# M3V6 register map
File version: 0.1
Registers are 32-bit, read-write, reset 0x0 unless marked. A register's access mark holds for its fields unless they carry their own. Offsets are from the block's base; [hi:lo] are bit positions; {n}, {i} and the like mark numbered series.

## PM — General Purpose Input_Output Port (PM)
Base 0x40000300
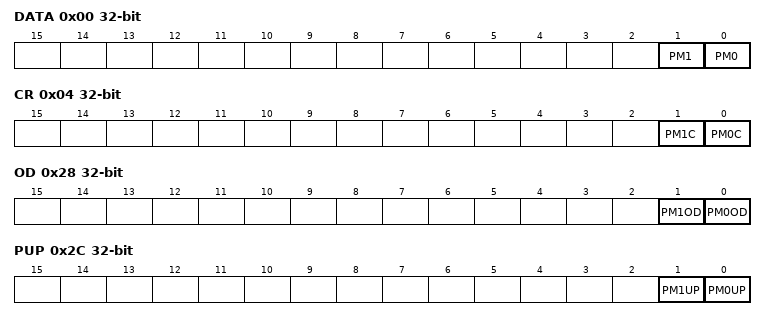
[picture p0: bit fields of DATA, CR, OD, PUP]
0x00 DATA — PM Data Register
  [1] PM1, [0] PM0
0x04 CR — PM Control Register
  [1] PM1C, [0] PM0C
0x28 OD — PM Open Drain Control Register
  [1] PM1OD, [0] PM0OD
0x2C PUP — PM Pull-Up Control Register
  [1] PM1UP, [0] PM0UP
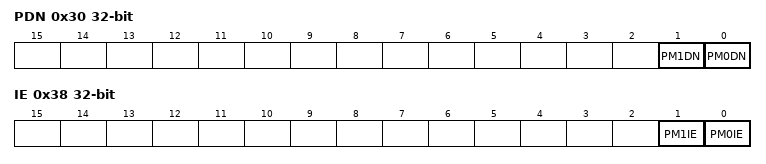
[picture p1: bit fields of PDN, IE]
0x30 PDN — PM Pull-Down Control Register
  [1] PM1DN, [0] PM0DN
0x38 IE — PM Input Enable Control Register
  [1] PM1IE, [0] PM0IE

## PN — General Purpose Input_Output Port (PN)
Base 0x40000340
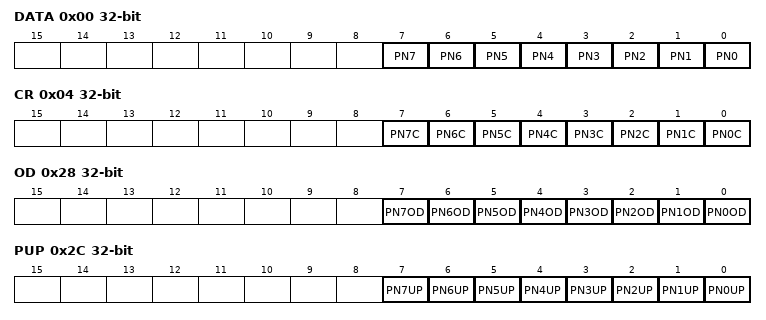
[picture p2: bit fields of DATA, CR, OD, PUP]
0x00 DATA — PN Data Register
  [n] PN{n} (n=0..7)
0x04 CR — PN Control Register
  [n] PN{n}C (n=0..7)
0x0C FR2 — PN Function Register 2
  [7] PN7F2
0x28 OD — PN Open Drain Control Register
  [n] PN{n}OD (n=0..7)
0x2C PUP — PN Pull-Up Control Register
  [n] PN{n}UP (n=0..7)
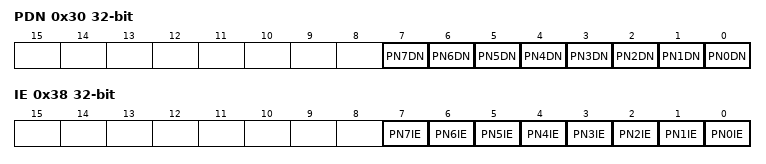
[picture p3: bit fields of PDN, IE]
0x30 PDN — PN Pull-Down Control Register
  [n] PN{n}DN (n=0..7)
0x38 IE — PN Input Enable Control Register
  [n] PN{n}IE (n=0..7)

## PP — General Purpose Input_Output Port (PP)
Base 0x40000380
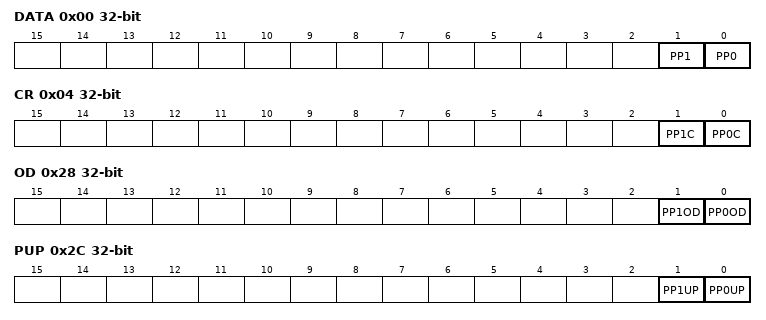
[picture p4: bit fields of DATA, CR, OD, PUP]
0x00 DATA — PP Data Register
  [1] PP1, [0] PP0
0x04 CR — PP Control Register
  [1] PP1C, [0] PP0C
0x28 OD — PP Open Drain Control Register
  [1] PP1OD, [0] PP0OD
0x2C PUP — PP Pull-Up Control Register
  [1] PP1UP, [0] PP0UP
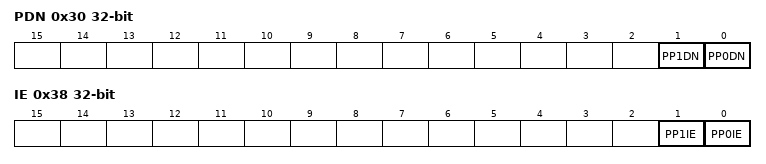
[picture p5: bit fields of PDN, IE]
0x30 PDN — PP Pull-Down Control Register
  [1] PP1DN, [0] PP0DN
0x38 IE — PP Input Enable Control Register
  [1] PP1IE, [0] PP0IE

## TB0 — 16-bit Timer_Event Counter (TB)
Base 0x40010000
Same registers: TB1 0x40010040, TB2 0x40010080, TB3 0x400100C0, TB4 0x40010100, TB5 0x40010140, TB6 0x40010180, TB7 0x400101C0
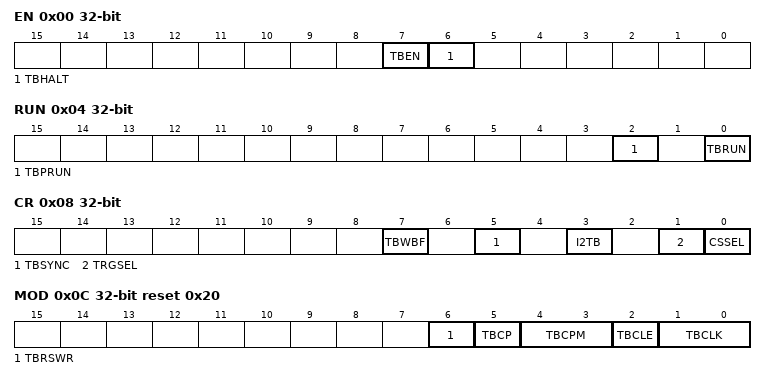
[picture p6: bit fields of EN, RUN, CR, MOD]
0x00 EN — TB Enable Register
  [7] TBEN, [6] TBHALT
0x04 RUN — TB RUN Register
  [2] TBPRUN, [0] TBRUN
0x08 CR — TB Control Register
  [7] TBWBF, [5] TBSYNC, [3] I2TB, [1] TRGSEL, [0] CSSEL
0x0C MOD reset 0x20 — TB Mode Register
  [6] TBRSWR, [5] TBCP wo, [4:3] TBCPM, [2] TBCLE, [1:0] TBCLK
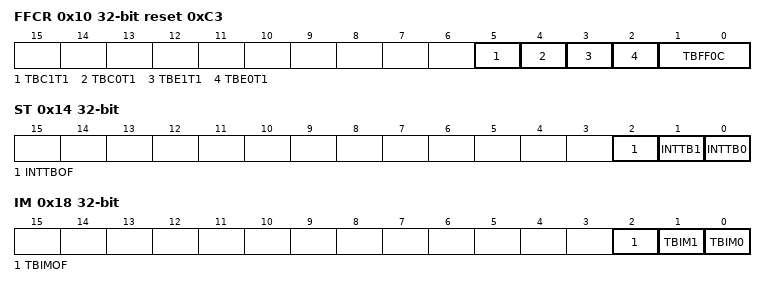
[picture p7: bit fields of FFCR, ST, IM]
0x10 FFCR reset 0xC3 — TB Flip-Flop Control Register
  [5] TBC1T1, [4] TBC0T1, [3] TBE1T1, [2] TBE0T1, [1:0] TBFF0C
0x14 ST ro — TB Status Register
  [2] INTTBOF, [1] INTTB1, [0] INTTB0
0x18 IM — TB Interrupt Mask Register
  [2] TBIMOF, [1] TBIM1, [0] TBIM0
0x1C UC ro — TB Read Capture Register
  [15:0] TBUC
0x20 RG0 — TB RG0 Timer Register
  [15:0] TBRG0
0x24 RG1 — TB RG1 Timer Register
  [15:0] TBRG1
0x28 CP0 ro (reset mask 0xFFFF0000) — TB CP0 Capture Register
  [15:0] TBCP0
0x2C CP1 ro (reset mask 0xFFFF0000) — TB CP1 Capture Register
  [15:0] TBCP1

## SBI — Serial Bus Interface (SBI)
Base 0x40020000
0x00 CR0 — SBI Control Register 0
  [7] SBIEN
0x04 CR1_A reset 0x9 — SBI Control Register 1 (I2C Mode)
  [7:5] BC, [4] ACK, [2:1] SCK12, [0] SWRMON ro, [0] SCK0 wo
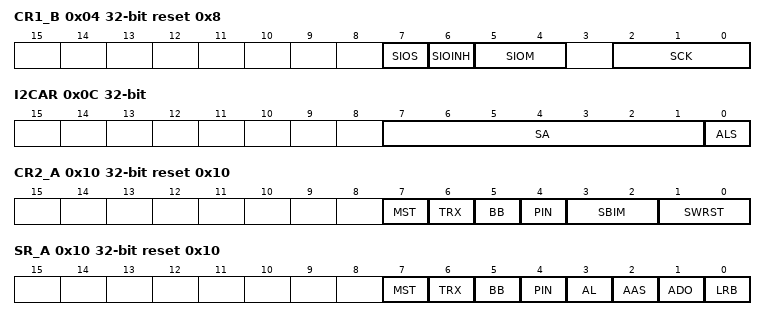
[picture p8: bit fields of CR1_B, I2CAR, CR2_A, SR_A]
0x04 CR1_B reset 0x8 (SBI_CR1 view) — SBI Control Register 1 (SIO Mode)
  [7] SIOS, [6] SIOINH, [5:4] SIOM, [2:0] SCK
0x08 DBR — SBI Data Buffer Register
  [7:0] DB
0x0C I2CAR — SBI I2C Bus Address Register
  [7:1] SA, [0] ALS
0x10 CR2_A wo reset 0x10 — SBI Control Register 2 (I2C Mode)
  [7] MST, [6] TRX, [5] BB, [4] PIN, [3:2] SBIM, [1:0] SWRST
0x10 CR2_B wo reset 0xF3 (SBI_CR2 view) — SBI Control Register 2 (SIO Mode)
  [3:2] SBIM
0x10 SR_A ro reset 0x10 — SBI Status Register (I2C Mode)
  [7] MST, [6] TRX, [5] BB, [4] PIN, [3] AL, [2] AAS, [1] ADO, [0] LRB
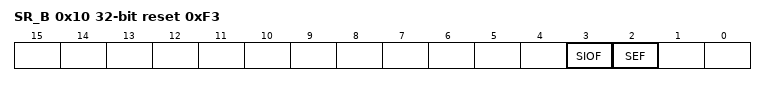
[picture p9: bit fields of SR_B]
0x10 SR_B ro reset 0xF3 (SBI_SR view) — SBI Status Register (SIO Mode)
  [3] SIOF, [2] SEF
0x14 BR0 reset 0xBE — SBI Baud Rate Register 0
  [6] I2SBI

## SC0 — Serial Channel (SC)
Base 0x40020080
Same registers: SC1 0x400200C0, SC2 0x40020100
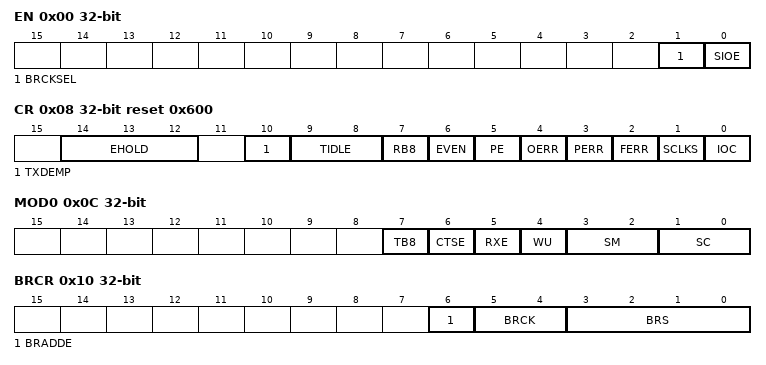
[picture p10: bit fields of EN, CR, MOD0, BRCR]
0x00 EN — SC Enable Register
  [1] BRCKSEL, [0] SIOE
0x04 BUF — SC Buffer Register
  [7:0] TB_RB
0x08 CR reset 0x600 — SC Control Register
  [14:12] EHOLD, [10] TXDEMP, [9:8] TIDLE, [7] RB8 ro, [6] EVEN, [5] PE, [4] OERR ro, [3] PERR ro, [2] FERR ro, [1] SCLKS, [0] IOC
0x0C MOD0 — SC Mode Control Register 0
  [7] TB8, [6] CTSE, [5] RXE, [4] WU, [3:2] SM, [1:0] SC
0x10 BRCR — SC Baud Rate Generator Control Register
  [6] BRADDE, [5:4] BRCK, [3:0] BRS
0x14 BRADD — SC Baud Rate Generator Control Register 2
  [3:0] BRK
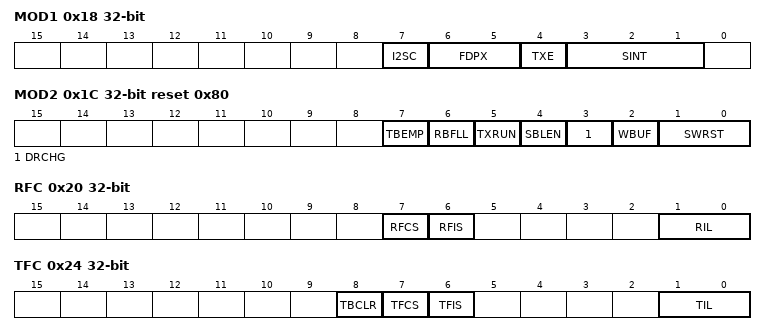
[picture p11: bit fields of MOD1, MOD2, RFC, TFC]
0x18 MOD1 — SC Mode Control Register 1
  [7] I2SC, [6:5] FDPX, [4] TXE, [3:1] SINT
0x1C MOD2 reset 0x80 — SC Mode Control Register 2
  [7] TBEMP ro, [6] RBFLL ro, [5] TXRUN ro, [4] SBLEN, [3] DRCHG, [2] WBUF, [1:0] SWRST
0x20 RFC — SC RX FIFO Configuration Register
  [7] RFCS wo, [6] RFIS, [1:0] RIL
0x24 TFC — SC TX FIFO Configuration Register
  [8] TBCLR wo, [7] TFCS wo, [6] TFIS, [1:0] TIL
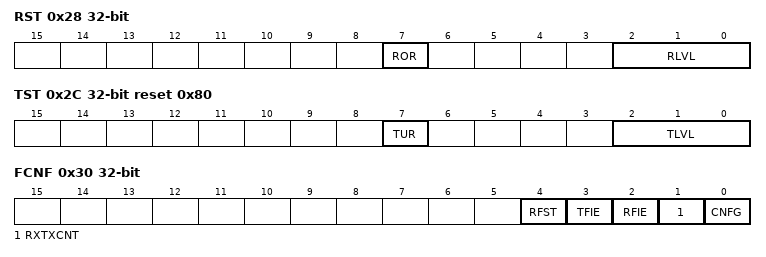
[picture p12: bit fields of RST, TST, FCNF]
0x28 RST ro — SC RX FIFO Status Register
  [7] ROR, [2:0] RLVL
0x2C TST ro reset 0x80 — SC TX FIFO Status Register
  [7] TUR, [2:0] TLVL
0x30 FCNF — SC FIFO Configuration Register
  [4] RFST, [3] TFIE, [2] RFIE, [1] RXTXCNT, [0] CNFG
